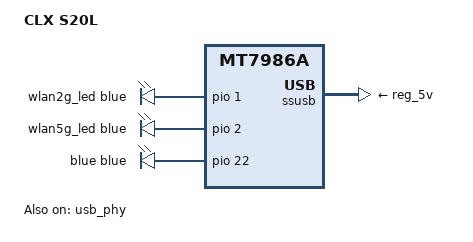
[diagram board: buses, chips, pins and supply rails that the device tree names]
// SPDX-License-Identifier: GPL-2.0-or-later OR MIT

/dts-v1/;
#include "mt7986a-clx-s20l.dtsi"

/ {
	model = "CLX S20L";
	compatible = "clx,s20l", "mediatek,mt7986a";

	aliases {
		serial0 = &uart0;
		led-boot = &blue;
		led-failsafe = &blue;
		led-running = &blue;
		led-upgrade = &blue;
	};

	leds {
		compatible = "gpio-leds";

		wlan2g_led: wlan-2ghz {
			function = LED_FUNCTION_WLAN_2GHZ;
			color = <LED_COLOR_ID_BLUE>;
			gpios = <&pio 1 GPIO_ACTIVE_HIGH>;
		};

		wlan5g_led: wlan-5ghz {
			function = LED_FUNCTION_WLAN_5GHZ;
			color = <LED_COLOR_ID_BLUE>;
			gpios = <&pio 2 GPIO_ACTIVE_HIGH>;
		};

		blue: status {
			function = LED_FUNCTION_STATUS;
			color = <LED_COLOR_ID_BLUE>;
			gpios = <&pio 22 GPIO_ACTIVE_HIGH>;
			linux,default-trigger = "heartbeat";
		};
	};
};

&ssusb {
	vusb33-supply = <&reg_3p3v>;
	vbus-supply = <&reg_5v>;
	status = "okay";
};

&usb_phy {
	status = "okay";
};
